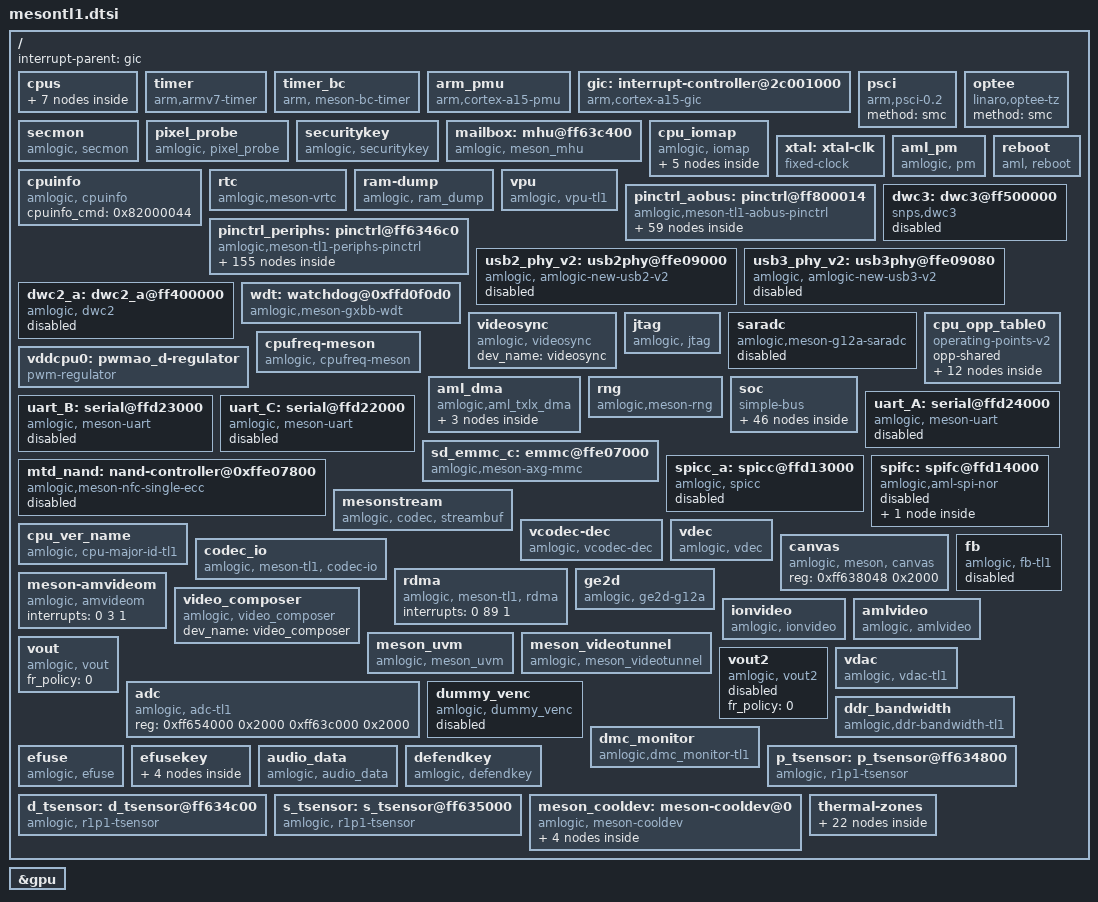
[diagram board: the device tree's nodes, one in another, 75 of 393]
// SPDX-License-Identifier: (GPL-2.0+ OR MIT)
/*
 * Copyright (c) 2021 Amlogic, Inc. All rights reserved.
 */

#include <dt-bindings/interrupt-controller/arm-gic.h>
#include <dt-bindings/gpio/meson-tl1-gpio.h>
#include <dt-bindings/gpio/gpio.h>
#include <dt-bindings/input/meson_rc.h>
#include <dt-bindings/input/input.h>
#include <dt-bindings/pwm/pwm.h>
#include <dt-bindings/pwm/meson.h>
#include <dt-bindings/clock/tl1-clkc.h>
#include <dt-bindings/clock/tl1-aoclkc.h>
#include <dt-bindings/clock/amlogic,tl1-audio-clk.h>
#include "mesong12a-bifrost.dtsi"
#include <dt-bindings/iio/adc/amlogic-saradc.h>
#include <dt-bindings/thermal/thermal.h>
#include "meson-ir-map.dtsi"
/ {
	interrupt-parent = <&gic>;
	#address-cells = <1>;
	#size-cells = <1>;

	cpus:cpus {
		#address-cells = <1>;
		#size-cells = <0>;
		#cooling-cells = <2>;/* min followed by max */
		CPU0:cpu@0 {
			device_type = "cpu";
			compatible = "arm,cortex-a9";
			reg = <0x0>;
			//timer=<&timer_a>;
			enable-method = "psci";
			clocks = <&clkc CLKID_CPU_CLK>,
				<&clkc CLKID_CPU_CLK_DYN>,
				<&clkc CLKID_SYS_PLL>,
				<&clkc CLKID_DSU_CLK>,
				<&clkc CLKID_DSU_CLK_FINAL>;
			clock-names = "core_clk",
				"low_freq_clk_parent",
				"high_freq_clk_parent",
				"dsu_clk",
				"dsu_pre_parent";
			operating-points-v2 = <&cpu_opp_table0>;
			/*set dynamic gp1 clk to val * 1000 *1000*/
			//dynamic_gp1_clk = <1000>;
			cpu-supply = <&vddcpu0>;
			cpu-idle-states = <&CPU_SLEEP_0 &SYSTEM_SLEEP_0>;
			//cpu-idle-states = <&SYSTEM_SLEEP_0>;
			voltage-tolerance = <0>;
			clock-latency = <50000>;
			#cooling-cells = <2>;
		};

		CPU1:cpu@1 {
			device_type = "cpu";
			compatible = "arm,cortex-a9";
			reg = <0x1>;
			//timer=<&timer_b>;
			enable-method = "psci";
			//clocks = <&clkc CLKID_CPU_CLK>,
			//	<&clkc CLKID_CPU_FCLK_P>,
			//	<&clkc CLKID_SYS_PLL>,
			//	<&clkc CLKID_DSU_CLK>,
			//	<&clkc CLKID_DSU_PRE_CLK>;
			//clock-names = "core_clk",
			//	"low_freq_clk_parent",
			//	"high_freq_clk_parent",
			//	"dsu_clk",
			//	"dsu_pre_parent";
			operating-points-v2 = <&cpu_opp_table0>;
			/*set dynamic gp1 clk to val * 1000 *1000*/
			dynamic_gp1_clk = <1000>;
			cpu-supply = <&vddcpu0>;
			cpu-idle-states = <&CPU_SLEEP_0 &SYSTEM_SLEEP_0>;
			//cpu-idle-states = <&SYSTEM_SLEEP_0>;
			voltage-tolerance = <0>;
			clock-latency = <50000>;
		};

		CPU2:cpu@2 {
			device_type = "cpu";
			compatible = "arm,cortex-a9";
			reg = <0x2>;
			//timer=<&timer_c>;
			enable-method = "psci";
			//clocks = <&clkc CLKID_CPU_CLK>,
			//	<&clkc CLKID_CPU_FCLK_P>,
			//	<&clkc CLKID_SYS_PLL>,
			//	<&clkc CLKID_DSU_CLK>,
			//	<&clkc CLKID_DSU_PRE_CLK>;
			//clock-names = "core_clk",
			//	"low_freq_clk_parent",
			//	"high_freq_clk_parent",
			//	"dsu_clk",
			//	"dsu_pre_parent";
			operating-points-v2 = <&cpu_opp_table0>;
			/*set dynamic gp1 clk to val * 1000 *1000*/
			dynamic_gp1_clk = <1000>;
			cpu-supply = <&vddcpu0>;
			cpu-idle-states = <&CPU_SLEEP_0 &SYSTEM_SLEEP_0>;
			//cpu-idle-states = <&SYSTEM_SLEEP_0>;
			voltage-tolerance = <0>;
			clock-latency = <50000>;
		};

		CPU3:cpu@3 {
			device_type = "cpu";
			compatible = "arm,cortex-a9";
			reg = <0x3>;
			//timer=<&timer_d>;
			enable-method = "psci";
			//clocks = <&clkc CLKID_CPU_CLK>,
			//	<&clkc CLKID_CPU_FCLK_P>,
			//	<&clkc CLKID_SYS_PLL>,
			//	<&clkc CLKID_DSU_CLK>,
			//	<&clkc CLKID_DSU_PRE_CLK>;
			//clock-names = "core_clk",
			//	"low_freq_clk_parent",
			//	"high_freq_clk_parent",
			//	"dsu_clk",
			//	"dsu_pre_parent";
			operating-points-v2 = <&cpu_opp_table0>;
			/*set dynamic gp1 clk to val * 1000 *1000*/
			dynamic_gp1_clk = <1000>;
			cpu-supply = <&vddcpu0>;
			cpu-idle-states = <&CPU_SLEEP_0 &SYSTEM_SLEEP_0>;
			//cpu-idle-states = <&SYSTEM_SLEEP_0>;
			voltage-tolerance = <0>;
			clock-latency = <50000>;
		};

		idle-states {
			entry-method = "arm,psci";
			CPU_SLEEP_0: cpu-sleep-0 {
				compatible = "arm,idle-state";
				arm,psci-suspend-param = <0x0010000>;
				local-timer-stop;
				entry-latency-us = <4000>;
				exit-latency-us = <4000>;
				min-residency-us = <9000>;
			};
			SYSTEM_SLEEP_0: system-sleep-0 {
				compatible = "arm,idle-state";
				arm,psci-suspend-param = <0x0000000>;
				entry-latency-us = <0x3fffffff>;
				exit-latency-us = <0x40000000>;
				min-residency-us = <0xffffffff>;
			};
		};
	};

	timer {
		compatible = "arm,armv7-timer";
		interrupts = <GIC_PPI 13 0xff01>,
			     <GIC_PPI 14 0xff01>,
			     <GIC_PPI 11 0xff01>,
			     <GIC_PPI 10 0xff01>;
	};

	timer_bc {
		compatible = "arm, meson-bc-timer";
		reg = <0xffd0f190  0x4  0xffd0f194  0x4>;
		timer_name = "Meson TimerF";
		clockevent-rating =<300>;
		clockevent-shift =<20>;
		clockevent-features =<0x23>;
		interrupts = <0 60 1>;
		bit_enable =<16>;
		bit_mode =<12>;
		bit_resolution =<0>;
	};

	arm_pmu {
		compatible = "arm,cortex-a15-pmu";
		/* clusterb-enabled; */
		interrupts = <GIC_SPI 137 IRQ_TYPE_LEVEL_HIGH>;
		reg = <0xff634680 0x4>;
		cpumasks = <0xf>;
		/* default 10ms */
		relax-timer-ns = <10000000>;
		/* default 10000us */
		max-wait-cnt = <10000>;
	};

	gic: interrupt-controller@2c001000 {
		compatible = "arm,cortex-a15-gic", "arm,cortex-a9-gic";
		#interrupt-cells = <3>;
		#address-cells = <0>;
		interrupt-controller;
		reg = <0xffc01000 0x1000>,
		      <0xffc02000 0x0100>;
		interrupts = <GIC_PPI 9 0xf04>;
	};

	psci {
		compatible = "arm,psci-0.2";
		method = "smc";
	};

	secmon {
		compatible = "amlogic, secmon";
		memory-region = <&secmon_reserved>;
		in_base_func = <0x82000020>;
		out_base_func = <0x82000021>;
		inout_size_func = <0x8200002a>;
		reserve_mem_size = <0x00300000>;
	};

	optee {
		compatible = "linaro,optee-tz";
		method = "smc";
	};

	pixel_probe: pixel_probe {
		compatible = "amlogic, pixel_probe";
		vpp_probe_func = <0x820000f1>;
		vdin_probe_func = <0x820000f2>;
	};

	securitykey {
		compatible = "amlogic, securitykey";
		status = "okay";
		storage_query = <0x82000060>;
		storage_read = <0x82000061>;
		storage_write = <0x82000062>;
		storage_tell = <0x82000063>;
		storage_verify = <0x82000064>;
		storage_status = <0x82000065>;
		storage_list = <0x82000067>;
		storage_remove = <0x82000068>;
		storage_in_func = <0x82000023>;
		storage_out_func = <0x82000024>;
		storage_block_func = <0x82000025>;
		storage_size_func = <0x82000027>;
		storage_set_enctype = <0x8200006A>;
		storage_get_enctype = <0x8200006B>;
		storage_version = <0x8200006C>;
	};

	mailbox: mhu@ff63c400 {
		status = "okay";
		compatible = "amlogic, meson_mhu";
		reg = <0xff63c400 0x4c>,   /* MHU registers */
		      <0xfffd7000 0x800>;   /* Payload area */
		interrupts = <GIC_SPI 209 IRQ_TYPE_EDGE_RISING>,
			     <GIC_SPI 210 IRQ_TYPE_EDGE_RISING>;
		#mbox-cells = <1>;
		mbox-names = "cpu_to_scp_low", "cpu_to_scp_high";
		mboxes = <&mailbox 0 &mailbox 1>;
	};

	cpu_iomap {
		compatible = "amlogic, iomap";
		#address-cells = <1>;
		#size-cells = <1>;
		ranges;

		io_cbus_base {
			reg = <0xffd00000 0x101000>;
		};
		io_apb_base {
			reg = <0xffe01000 0x19f000>;
		};
		io_aobus_base {
			reg = <0xff800000 0x100000>;
		};
		io_vapb_base {
			reg = <0xff900000 0x200000>;
		};
		io_hiu_base {
			reg = <0xff63c000 0x2000>;
		};
	};

	xtal: xtal-clk {
		compatible = "fixed-clock";
		clock-frequency = <24000000>;
		clock-output-names = "xtal";
		#clock-cells = <0>;
	};

	aml_pm {
		compatible = "amlogic, pm";
		status = "okay";
		device_name = "aml_pm";
		reg = <0xff8000a8 0x4>,
			<0xff80023c 0x4>,
			<0xff638634 0x4>, /* dmc_asr */
			<0xff63c19c 0x4>; /* cpu gp1 */
		reg-names = "dmc_asr",
			"cpu";
		dmc_asr_value = <0x3fe00>;
		//clocks = <&clkc CLKID_SWITCH_CLK81>,
		//	<&clkc CLKID_CLK81>,
		//	<&clkc CLKID_FIXED_PLL>,
		//	<&xtal>;
		//clock-names = "switch_clk81",
		//	"clk81",
		//	"fixed_pll",
		//	"xtal";
	};

	cpuinfo {
		compatible = "amlogic, cpuinfo";
		status = "okay";
		cpuinfo_cmd = <0x82000044>;
	};

	rtc{
		compatible = "amlogic,meson-vrtc";
		reg = <0xff8000a8 0x4>;	/*AO_DEBUG_REG2*/
		status = "okay";
		mboxes = <&mailbox 1>;
		mbox_data_packet;
	};

	reboot {
		compatible = "aml, reboot";
		sys_reset = <0x84000009>;
		sys_poweroff = <0x84000008>;
		reg = <0xff80023c 0x4>; /* SEC_AO_SEC_SD_CFG15 */
		status = "okay";
	};

	ram-dump {
		compatible = "amlogic, ram_dump";
		status = "okay";
		reg = <0xFF6345E0 4>;
		reg-names = "PREG_STICKY_REG8";
		store_device = "data";
	};

	securitykey {
		compatible = "amlogic, securitykey";
		status = "okay";
		storage_query = <0x82000060>;
		storage_read = <0x82000061>;
		storage_write = <0x82000062>;
		storage_tell = <0x82000063>;
		storage_verify = <0x82000064>;
		storage_status = <0x82000065>;
		storage_list = <0x82000067>;
		storage_remove = <0x82000068>;
		storage_in_func = <0x82000023>;
		storage_out_func = <0x82000024>;
		storage_block_func = <0x82000025>;
		storage_size_func = <0x82000027>;
		storage_set_enctype = <0x8200006A>;
		storage_get_enctype = <0x8200006B>;
		storage_version = <0x8200006C>;
	};

	vpu {
		compatible = "amlogic, vpu-tl1";
		status = "okay";
		reg =	<0xff63c000 0x200  /* hiu */
			 0xff900000 0x50000 /* vcbus */
			 0xffd00000 0x10a0  /* cbus */
			 0xff800000 0x100>; /* aobus */
		clocks = <&clkc CLKID_VAPB_SEL>,
			<&clkc CLKID_CLK81_VPU_INTR>,
			<&clkc CLKID_VPU_0>,
			<&clkc CLKID_VPU_1>,
			<&clkc CLKID_VPU>;
		clock-names = "vapb_clk",
			"vpu_intr_gate",
			"vpu_clk0",
			"vpu_clk1",
			"vpu_clk";
		clk_level = <7>;
		/* 0: 100.0M    1: 166.7M    2: 200.0M    3: 250.0M */
		/* 4: 333.3M    5: 400.0M    6: 500.0M    7: 666.7M */
	};

	pinctrl_aobus: pinctrl@ff800014 {
		compatible = "amlogic,meson-tl1-aobus-pinctrl";
		#address-cells = <1>;
		#size-cells = <1>;
		ranges;

		gpio_ao: ao-bank@ff800014 {
			reg = <0xff800014 0x8>,
				  <0xff800024 0x14>,
				  <0xff80001c 0x8>;
			reg-names = "mux", "gpio", "ds";
			gpio-controller;
			#gpio-cells = <2>;
			gpio-ranges = <&pinctrl_aobus 0 0 16>;
		};

		aoceca_mux:aoceca_mux {
			mux {
				groups = "cec_ao_a";
				function = "cec_ao";
			};
		};

		aocecb_mux:aocecb_mux {
			mux {
				groups = "cec_ao_b";
				function = "cec_ao";
			};
		};
	};

	pinctrl_periphs: pinctrl@ff6346c0 {
		compatible = "amlogic,meson-tl1-periphs-pinctrl";
		#address-cells = <1>;
		#size-cells = <1>;
		ranges;

		gpio: banks@ff6346c0 {
			reg = <0xff6346c0 0x40>,
				  <0xff6344e8 0x18>,
				  <0xff634520 0x18>,
				  <0xff634440 0x4c>,
				  <0xff634740 0x1c>;
			reg-names = "mux",
				"pull",
				"pull-enable",
				"gpio",
				"ds";
			gpio-controller;
			#gpio-cells = <2>;
			gpio-ranges = <&pinctrl_periphs 0 0 87>;
		};

		hdmirx_a_mux:hdmirx_a_mux {
			mux {
				groups = "hdmirx_a_hpd", "hdmirx_a_det",
					"hdmirx_a_sda", "hdmirx_a_sck";
				function = "hdmirx_a";
			};
		};

		hdmirx_b_mux:hdmirx_b_mux {
			mux {
				groups = "hdmirx_b_hpd", "hdmirx_b_det",
					"hdmirx_b_sda", "hdmirx_b_sck";
				function = "hdmirx_b";
			};
		};

		hdmirx_c_mux:hdmirx_c_mux {
			mux {
				groups = "hdmirx_c_hpd", "hdmirx_c_det",
					"hdmirx_c_sda", "hdmirx_c_sck";
				function = "hdmirx_c";
			};
		};

	};

	dwc3: dwc3@ff500000 {
		compatible = "snps,dwc3";
		status = "disabled";
		reg = <0xff500000 0x100000>;
		interrupts = <0 30 4>;
		usb-phy = <&usb2_phy_v2>, <&usb3_phy_v2>;
		cpu-type = "gxl";
		clock-src = "usb3.0";
		clocks = <&clkc CLKID_CLK81_USB_GENERAL>;
		clock-names = "usb_general";
	};

	usb2_phy_v2: usb2phy@ffe09000 {
		compatible = "amlogic, amlogic-new-usb2-v2";
		status = "disabled";
		reg = <0xffe09000 0x80
				0xffd01008 0x100
				0xff636000 0x2000
				0xff63a000 0x2000
				0xff658000 0x2000>;
		pll-setting-1 = <0x09400414>;
		pll-setting-2 = <0x927E0000>;
		pll-setting-3 = <0xac5f69e5>;
		pll-setting-4 = <0xfe18>;
		pll-setting-5 = <0x8000fff>;
		pll-setting-6 = <0x78000>;
		pll-setting-7 = <0xe0004>;
		pll-setting-8 = <0xe000c>;
		version = <1>;
	};

	usb3_phy_v2: usb3phy@ffe09080 {
		compatible = "amlogic, amlogic-new-usb3-v2";
		status = "disabled";
		reg = <0xffe09080 0x20>;
		phy-reg = <0xff646000>;
		phy-reg-size = <0x2000>;
		usb2-phy-reg = <0xffe09000>;
		usb2-phy-reg-size = <0x80>;
		interrupts = <0 16 4>;
	};

	dwc2_a: dwc2_a@ff400000 {
		compatible = "amlogic, dwc2";
		status = "disabled";
		device_name = "dwc2_a";
		reg = <0xff400000 0x40000>;
		interrupts = <0 31 4>;
		pl-periph-id = <0>; /** lm name */
		clock-src = "usb1"; /** clock src */
		port-id = <0>;  /** ref to mach/usb.h */
		port-type = <2>;        /** 0: otg, 1: host, 2: slave */
		port-speed = <0>; /** 0: default, high, 1: full */
		port-config = <0>; /** 0: default */
		/*0:default,1:single,2:incr,3:incr4,4:incr8,5:incr16,6:disable*/
		port-dma = <0>;
		port-id-mode = <0>; /** 0: hardware, 1: sw_host, 2: sw_slave*/
		usb-fifo = <728>;
		cpu-type = "v2";
		phy-reg = <0xffe09000>;
		phy-reg-size = <0xa0>;
		/** phy-interface: 0x0: amlogic-v1 phy, 0x1: synopsys phy **/
		/**                0x2: amlogic-v2 phy                    **/
		phy-interface = <0x2>;
		clocks = <&clkc CLKID_CLK81_USB_GENERAL
					&clkc CLKID_CLK81_USB1_TO_DDR>;
		clock-names = "usb_general",
					"usb1";
	};

	wdt: watchdog@0xffd0f0d0 {
		compatible = "amlogic,meson-gxbb-wdt";
		status = "okay";
		/* 0:userspace, 1:kernel */
		amlogic,feed_watchdog_mode = <1>;
		reg = <0xffd0f0d0 0x10>;
		clocks = <&xtal>;
	};

	videosync {
		compatible = "amlogic, videosync";
		dev_name = "videosync";
		status = "okay";
	};

	jtag {
		compatible = "amlogic, jtag";
		status = "okay";
		select = "disable"; /* disable/apao */
		pinctrl-names="jtag_a_pins";
		pinctrl-0=<&jtag_apao_pins>;
	};

	saradc: saradc {
		compatible = "amlogic,meson-g12a-saradc";
		status = "disabled";
		#io-channel-cells = <1>;
		clocks = <&xtal>,
			 <&clkc_AO CLKID_AO_SAR_ADC>,
			 <&clkc_AO CLKID_AO_SAR_ADC_CLK>,
			 <&clkc_AO CLKID_AO_SAR_ADC_SEL>;
		clock-names = "clkin", "core", "adc_clk", "adc_sel";
		interrupts = <GIC_SPI 200 IRQ_TYPE_EDGE_RISING>;
		reg = <0xff809000 0x48>;
	};

	vddcpu0: pwmao_d-regulator {
		compatible = "pwm-regulator";
		pwms = <&pwm_AO_cd MESON_PWM_1 1500 0>;
		regulator-name = "vddcpu0";
		regulator-min-microvolt = <689000>;
		regulator-max-microvolt = <1049000>;
		regulator-always-on;
		max-duty-cycle = <1500>;
		/* Voltage Duty-Cycle */
		voltage-table = <1049000 0>,
				<1039000 3>,
				<1029000 6>,
				<1019000 9>,
				<1009000 12>,
				<999000 14>,
				<989000 17>,
				<979000 20>,
				<969000 23>,
				<959000 26>,
				<949000 29>,
				<939000 31>,
				<929000 34>,
				<919000 37>,
				<909000 40>,
				<899000 43>,
				<889000 45>,
				<879000 48>,
				<869000 51>,
				<859000 54>,
				<849000 56>,
				<839000 59>,
				<829000 62>,
				<819000 65>,
				<809000 68>,
				<799000 70>,
				<789000 73>,
				<779000 76>,
				<769000 79>,
				<759000 81>,
				<749000 84>,
				<739000 87>,
				<729000 89>,
				<719000 92>,
				<709000 95>,
				<699000 98>,
				<689000 100>;
				status = "okay";
	};

	cpu_opp_table0: cpu_opp_table0 {
		compatible = "operating-points-v2";
		opp-shared;

		opp00 {
			opp-hz = /bits/ 64 <100000000>;
			opp-microvolt = <769000>;
		};
		opp01 {
			opp-hz = /bits/ 64 <250000000>;
			opp-microvolt = <769000>;
		};
		opp02 {
			opp-hz = /bits/ 64 <500000000>;
			opp-microvolt = <769000>;
		};
		opp03 {
			opp-hz = /bits/ 64 <667000000>;
			opp-microvolt = <779000>;
		};
		opp04 {
			opp-hz = /bits/ 64 <1000000000>;
			opp-microvolt = <789000>;
		};
		opp05 {
			opp-hz = /bits/ 64 <1200000000>;
			opp-microvolt = <789000>;
		};
		opp06 {
			opp-hz = /bits/ 64 <1404000000>;
			opp-microvolt = <799000>;
		};
		opp07 {
			opp-hz = /bits/ 64 <1500000000>;
			opp-microvolt = <809000>;
		};
		opp08 {
			opp-hz = /bits/ 64 <1608000000>;
			opp-microvolt = <819000>;
		};
		opp09 {
			opp-hz = /bits/ 64 <1704000000>;
			opp-microvolt = <859000>;
		};
		opp10 {
			opp-hz = /bits/ 64 <1800000000>;
			opp-microvolt = <919000>;
		};
		opp11 {
			opp-hz = /bits/ 64 <1908000000>;
			opp-microvolt = <989000>;
		};
	};

	cpufreq-meson {
		compatible = "amlogic, cpufreq-meson";
		status = "okay";
	};

	aml_dma {
		compatible = "amlogic,aml_txlx_dma";
		reg = <0xff63e000 0x48>;
		interrupts = <0 180 1>;

		aml_aes {
			compatible = "amlogic,aes_g12a_dma";
			dev_name = "aml_aes_dma";
			status = "okay";
		};

		aml_sha {
			compatible = "amlogic,sha_dma";
			dev_name = "aml_sha_dma";
			status = "okay";
		};

		aml_tdes {
			compatible = "amlogic,tdes_dma";
			dev_name = "aml_tdes_dma";
			status = "okay";
		};

	};

	rng {
		compatible = "amlogic,meson-rng";
		status = "okay";
		#address-cells = <1>;
		#size-cells = <1>;
		reg = <0xff630218 0x4>;
		quality = /bits/ 16 <1000>;
	};

	soc {
		compatible = "simple-bus";
		#address-cells = <1>;
		#size-cells = <1>;
		ranges;

		hiubus: hiubus@ff63c000 {
			compatible = "simple-bus";
			reg = <0xff63c000 0x2000>;
			#address-cells = <1>;
			#size-cells = <1>;
			ranges = <0x0 0xff63c000 0x2000>;

			hhi: system-controller@0 {
				compatible = "amlogic,meson-gx-hhi-sysctrl",
						"simple-mfd", "syscon";
				reg = <0 0x400>;

				clkc: clock-controller {
					compatible = "amlogic,tl1-clkc";
					#clock-cells = <1>;
					clocks = <&xtal>;
					clock-names = "xtal";
				};
			};
		};/* end of hiubus*/

		audiobus: audiobus@0xff600000 {
			compatible = "amlogic, audio-controller", "simple-bus";
			#address-cells = <1>;
			#size-cells = <1>;
			reg = <0xff600000 0x10000>;
			ranges = <0x0 0xff600000 0x10000>;
			reg-names = "audio_bus";
			chip_id = <0x2E>;
			clkaudio:audio_clocks {
				compatible = "amlogic, tl1-audio-clocks";
				#clock-cells = <1>;
				reg = <0x0 0xb0>;
			};

			ddr_manager {
				compatible = "amlogic, tl1-audio-ddr-manager";
				interrupts = <
					GIC_SPI 148 IRQ_TYPE_EDGE_RISING
					GIC_SPI 149 IRQ_TYPE_EDGE_RISING
					GIC_SPI 150 IRQ_TYPE_EDGE_RISING
					GIC_SPI 48 IRQ_TYPE_EDGE_RISING
					GIC_SPI 152 IRQ_TYPE_EDGE_RISING
					GIC_SPI 153 IRQ_TYPE_EDGE_RISING
					GIC_SPI 154 IRQ_TYPE_EDGE_RISING
					GIC_SPI 49 IRQ_TYPE_EDGE_RISING
				>;
				interrupt-names =
					"toddr_a", "toddr_b", "toddr_c",
					"toddr_d",
					"frddr_a", "frddr_b", "frddr_c",
					"frddr_d";
			};
			pinctrl_audio: pinctrl {
				compatible = "amlogic, tl1-audio-pinctrl";
				status = "okay";
			};
		};/* end of audiobus*/

		demux: demux {
			compatible = "amlogic, dmx";
			status = "okay";

			interrupts = <GIC_SPI 23 IRQ_TYPE_EDGE_RISING
				GIC_SPI 5 IRQ_TYPE_EDGE_RISING
				GIC_SPI 53 IRQ_TYPE_EDGE_RISING
				GIC_SPI 19 IRQ_TYPE_EDGE_RISING
				GIC_SPI 25 IRQ_TYPE_EDGE_RISING
				GIC_SPI 17 IRQ_TYPE_EDGE_RISING>;
			interrupt-names = "demux0_irq",
				"demux1_irq",
				"demux2_irq",
				"dvr0_irq",
				"dvr1_irq",
				"dvr2_irq";
		};

		/* Sound iomap */
		aml_snd_iomap {
			compatible = "amlogic, snd-iomap";
			status = "okay";
			#address-cells=<1>;
			#size-cells=<1>;
			ranges;
			pdm_bus {
				reg = <0xFF601000 0x400>;
			};
			audiobus_base {
				reg = <0xFF600000 0x1000>;
			};
			audiolocker_base {
				reg = <0xFF601400 0x400>;
			};
			eqdrc_base {
				reg = <0xFF602000 0x2000>;
			};
			reset_base {
				reg = <0xFFD01000 0x1000>;
			};
			vad_base {
				reg = <0xFF601800 0x800>;
			};
		};

		cbus: cbus@ffd00000 {
			compatible = "simple-bus";
			reg = <0xffd00000 0x27000>;
			#address-cells = <1>;
			#size-cells = <1>;
			ranges = <0x0 0xffd00000 0x27000>;

			clk-measure@18000 {
				compatible = "amlogic,meson-tl1-clk-measure";
				reg = <0x18000 0x10>;
			};

			i2c0: i2c@1f000 {
				compatible = "amlogic,meson-i2c";
				status = "disabled";
				reg = <0x1f000 0x20>;
				interrupts = <GIC_SPI 21 IRQ_TYPE_EDGE_RISING>,
					<GIC_SPI 91 IRQ_TYPE_EDGE_RISING>;
				#address-cells = <1>;
				#size-cells = <0>;
				clocks = <&clkc CLKID_CLK81_I2C>;
				clock-frequency = <100000>;
			};

			i2c1: i2c@1e000 {
				compatible = "amlogic,meson-i2c";
				status = "disabled";
				reg = <0x1e000 0x20>;
				interrupts = <GIC_SPI 214 IRQ_TYPE_EDGE_RISING>,
					<GIC_SPI 92 IRQ_TYPE_EDGE_RISING>;
				#address-cells = <1>;
				#size-cells = <0>;
				clocks = <&clkc CLKID_CLK81_I2C>;
				clock-frequency = <100000>;
			};

			i2c2: i2c@1d000 {
				compatible = "amlogic,meson-i2c";
				status = "disabled";
				reg = <0x1d000 0x20>;
				interrupts = <GIC_SPI 215 IRQ_TYPE_EDGE_RISING>,
					<GIC_SPI 94 IRQ_TYPE_EDGE_RISING>;
				#address-cells = <1>;
				#size-cells = <0>;
				clocks = <&clkc CLKID_CLK81_I2C>;
				clock-frequency = <100000>;
			};

			i2c3: i2c@1c000 {
				compatible = "amlogic,meson-i2c";
				status = "disabled";
				reg = <0x1c000 0x20>;
				interrupts = <GIC_SPI 39 IRQ_TYPE_EDGE_RISING>,
					<GIC_SPI 95 IRQ_TYPE_EDGE_RISING>;
				#address-cells = <1>;
				#size-cells = <0>;
				//clocks = <&clkc CLKID_I2C>;
				clock-frequency = <100000>;
			};

			gpio_intc: interrupt-controller@f080 {
				compatible = "amlogic,meson-gpio-intc",
						"amlogic,meson-tl1-gpio-intc";
				reg = <0xf080 0x10>;
				interrupt-controller;
				#interrupt-cells = <2>;
				amlogic,channel-interrupts =
					<64 65 66 67 68 69 70 71>;
				status = "okay";
			};

			pwm_ab: pwm@1b000 {
				compatible = "amlogic,tl1-ee-pwm";
				reg = <0x1b000 0x20>;
				#pwm-cells = <3>;
				clocks = <&xtal>,
						<&xtal>,
						<&xtal>,
						<&xtal>;
				clock-names = "clkin0",
						"clkin1",
						"clkin2",
						"clkin3";
				/* default xtal 24m  clkin0-clkin2 and
				 * clkin1-clkin3 should be set the same
				 */
				status = "disabled";
			};

			pwm_cd: pwm@1a000 {
				compatible = "amlogic,tl1-ee-pwm";
				reg = <0x1a000 0x20>;
				#pwm-cells = <3>;
				clocks = <&xtal>,
						<&xtal>,
						<&xtal>,
						<&xtal>;
				clock-names = "clkin0",
						"clkin1",
						"clkin2",
						"clkin3";
				status = "disabled";
			};

			pwm_ef: pwm@19000 {
				compatible = "amlogic,tl1-ee-pwm";
				reg = <0x19000 0x20>;
				#pwm-cells = <3>;
				clocks = <&xtal>,
						<&xtal>,
						<&xtal>,
						<&xtal>;
				clock-names = "clkin0",
						"clkin1",
						"clkin2",
						"clkin3";
				status = "disabled";
			};

			spicc0: spi@13000 {
				compatible = "amlogic,meson-tl1-spicc",
					     "amlogic,meson-g12a-spicc";
				reg = <0x13000 0x44>;
				interrupts = <GIC_SPI 81 IRQ_TYPE_LEVEL_HIGH>;
				//clocks = <&clkc CLKID_SPICC0>,
				//	 <&clkc CLKID_SPICC0_COMP>;
				//clock-names = "core", "comp";
				#address-cells = <1>;
				#size-cells = <0>;
				status = "disabled";
			};

			spicc1: spi@15000 {
				compatible = "amlogic,meson-tl1-spicc",
					     "amlogic,meson-g12a-spicc";
				reg = <0x15000 0x44>;
				interrupts = <GIC_SPI 90 IRQ_TYPE_LEVEL_HIGH>;
				//clocks = <&clkc CLKID_SPICC1>,
				//	 <&clkc CLKID_SPICC1_COMP>;
				clock-names = "core", "comp";
				#address-cells = <1>;
				#size-cells = <0>;
				status = "disabled";
			};
		};

		eth_phy: mdio-multiplexer@0xff64c000 {
			compatible = "amlogic,g12a-mdio-mux";
			reg = <0xff64c000 0xa4>;

			clocks = <&clkc CLKID_CLK81_ETH_PHY>,
				 <&xtal>,
				 <&clkc CLKID_MPLL_50M>;
			clock-names = "pclk", "clkin0", "clkin1";
			mdio-parent-bus = <&mdio0>;
			#address-cells = <1>;
			#size-cells = <0>;
			enet_type = <0>;

			ext_mdio: mdio@0 {
				reg = <0>;
				#address-cells = <1>;
				#size-cells = <0>;
			};

			int_mdio: mdio@1 {
				reg = <1>;
				#address-cells = <1>;
				#size-cells = <0>;

				internal_ephy: ethernet_phy@8 {
					compatible = "ethernet-phy-id0180.3301",
						     "ethernet-phy-ieee802.3-c22";
					interrupts = <GIC_SPI 9 IRQ_TYPE_LEVEL_HIGH>;
					reg = <8>;
					max-speed = <100>;
				};
			};
		};

		ethmac: ethernet@ff3f0000 {
			compatible = "amlogic,meson-axg-dwmac",
				     "snps,dwmac-3.70a",
				     "snps,dwmac";
			reg = <0xff3f0000 0x10000>,
			      <0xff634540 0x8>;
			interrupts = <GIC_SPI 8 IRQ_TYPE_LEVEL_HIGH>;
			interrupt-names = "macirq";
			clocks = <&clkc CLKID_CLK81_ETH_CORE>,
				 <&clkc CLKID_FCLK_DIV2>,
				 <&clkc CLKID_MPLL_50M>;
			clock-names = "stmmaceth", "clkin0", "clkin1";
			rx-fifo-depth = <4096>;
			tx-fifo-depth = <2048>;
			/*1:inphy; 2:exphy;*/
			internal_phy = <1>;
			mc_val = <0x4be04>;
			status = "disabled";

			mdio0: mdio {
				#address-cells = <1>;
				#size-cells = <0>;
				compatible = "snps,dwmac-mdio";
			};
		};

		aobus: aobus@ff800000 {
			compatible = "simple-bus";
			reg = <0xff800000 0xb000>;
			#address-cells = <1>;
			#size-cells = <1>;
			ranges = <0x0 0xff800000 0xb000>;

			cpu_version {
				compatible = "amlogic,meson-gx-ao-secure", "syscon";
				reg = <0x140 0x140>;
			};

			rti: sys-ctrl@0 {
				compatible = "amlogic,meson-gx-ao-sysctrl",
						"simple-mfd", "syscon";
				reg = <0x0 0x100>;
				#address-cells = <1>;
				#size-cells = <1>;
				ranges = <0x0 0x0 0x100>;

				clkc_AO: clock-controller {
					compatible = "amlogic,meson-tl1-aoclkc";
					#clock-cells = <1>;
					clocks = <&xtal>, <&clkc CLKID_CLK81>;
					clock-names = "xtal", "mpeg-clk";
				};
			};

			pwm_AO_ab: pwm@7000 {
				compatible = "amlogic,tl1-ao-pwm";
				reg = <0x7000 0x20>;
				#pwm-cells = <3>;
				clocks = <&xtal>,
					 <&xtal>,
					 <&xtal>,
					 <&xtal>;
				clock-names = "clkin0",
					      "clkin1",
					      "clkin2",
					      "clkin3";
				status = "disabled";
			};

			pwm_AO_cd: pwm@2000 {
				compatible = "amlogic,tl1-ao-pwm";
				reg = <0x2000 0x20>;
				#pwm-cells = <3>;
				clocks = <&xtal>,
					 <&xtal>,
					 <&xtal>,
					 <&xtal>;
				clock-names = "clkin0",
					      "clkin1",
					      "clkin2",
					      "clkin3";
				status = "okay";
			};

			uart_AO: serial@3000 {
				compatible = "amlogic, meson-uart";
				reg = <0x3000 0x18>;
				interrupts = <0 193 1>;
				status = "okay";
				clocks = <&xtal>;
				clock-names = "clk_uart";
				xtal_tick_en = <2>;
				fifosize = < 64 >;
				/* 0 not support; 1 support */
				support-sysrq = <0>;
			};

			uart_AO_B: serial@4000 {
				compatible = "amlogic, meson-uart";
				reg = <0x4000 0x18>;
				interrupts = <0 197 1>;
				status = "disabled";
				clocks = <&xtal &clkc_AO CLKID_AO_UART2>;
				clock-names = "clk_uart", "clk_gate";
				fifosize = < 64 >;
				pinctrl-names = "default";
				pinctrl-0 = <&ao_b_uart_pins1>;
			};

			ir: ir@8040 {
				compatible = "amlogic, meson-ir";
				reg = <0x8040 0x44>,
					<0x8000 0x20>;
				status = "disable";
				protocol = <REMOTE_TYPE_NEC>;
				interrupts = <GIC_SPI 196 IRQ_TYPE_EDGE_RISING>;
				map = <&custom_maps>;
				max_frame_time = <200>;
			};

			irblaster: meson-irblaster@14c {
				compatible = "amlogic, meson_irblaster";
				reg = <0x14c 0x10>,
					<0x40 0x4>;
				#irblaster-cells = <2>;
				interrupts = <GIC_SPI 198 IRQ_TYPE_EDGE_RISING>;
				status = "disabled";
			};

			i2c_AO: i2c@5000 {
				compatible = "amlogic,meson-i2c";
				status = "disabled";
				reg = <0x05000 0x20>;
				interrupts = <GIC_SPI 195 IRQ_TYPE_EDGE_RISING>,
					<GIC_SPI 201 IRQ_TYPE_EDGE_RISING>;
				#address-cells = <1>;
				#size-cells = <0>;
				clocks = <&clkc_AO CLKID_AO_I2C_M0>;
				clock-frequency = <100000>;
			};

			i2c_AO_slave:i2c_slave@6000 {
				compatible = "amlogic, meson-i2c-slave";
				status = "disabled";
				reg = <0x6000 0x20>;
				interrupts = <GIC_SPI 194 IRQ_TYPE_EDGE_RISING>;
				pinctrl-names="default";
				pinctrl-0=<&i2c_ao_slave_pins>;
			};
		};/* end of aobus */

		ion_dev {
			compatible = "amlogic, ion_dev";
			status = "okay";
			memory-region = <&ion_cma_reserved
					 &ion_fb_reserved>;
		};/* end of ion_dev*/
	}; /* end of soc*/

	uart_A: serial@ffd24000 {
		compatible = "amlogic, meson-uart";
		reg = <0xffd24000 0x18>;
		interrupts = <0 26 1>;
		status = "disabled";
		clocks = <&xtal
			&clkc CLKID_CLK81_UART0>;
		clock-names = "clk_uart",
			"clk_gate";
		fifosize = < 128 >;
		pinctrl-names = "default";
		pinctrl-0 = <&a_uart_pins>;
	};

	uart_B: serial@ffd23000 {
		compatible = "amlogic, meson-uart";
		reg = <0xffd23000 0x18>;
		interrupts = <0 75 1>;
		status = "disabled";
		clocks = <&xtal
			&clkc CLKID_CLK81_UART1>;
		clock-names = "clk_uart",
			"clk_gate";
		fifosize = < 64 >;
		pinctrl-names = "default";
		pinctrl-0 = <&b_uart_pins>;
	};

	uart_C: serial@ffd22000 {
		compatible = "amlogic, meson-uart";
		reg = <0xffd22000 0x18>;
		interrupts = <0 93 1>;
		status = "disabled";
		clocks = <&xtal
			&clkc CLKID_CLK81_UART2>;
		clock-names = "clk_uart",
			"clk_gate";
		fifosize = < 64 >;
		pinctrl-names = "default";
		pinctrl-0 = <&c_uart_pins>;
	};

	sd_emmc_c: emmc@ffe07000 {
		status = "okay";
		compatible = "amlogic,meson-axg-mmc";
		reg = <0xffe07000 0x800>,
			<0xffe07000 0x4>,//<0xFF63C25C 0x4>,
			<0xffe07000 0x4>;
		interrupts = <GIC_SPI 191 IRQ_TYPE_EDGE_RISING>;
		clocks = <&clkc CLKID_CLK81_SD_EMMC_C>,
			<&clkc CLKID_SD_EMMC_C_SEL>,
			<&clkc CLKID_SD_EMMC_C>,
			<&xtal>,
			<&clkc CLKID_GP0_PLL>,
			<&clkc CLKID_GP0_PLL>;
		clock-names = "core","mux0","mux1",
				"clkin0","clkin1","clkin2";
		card_type = <1>;
		tx_delay = <0x10>;
		src_clk_rate = <792000000>;
		mmc_debug_flag;
		disable-wp;
		no-sdio;
		no-sd;
	};

	spicc_a: spicc@ffd13000 {
		compatible = "amlogic, spicc";
		status = "disabled";
		device_id = <0>;
		reg = <0xffd13000 0x3c>;
		//clocks = <&clkc CLKID_SPICC0>,
		//	<&clkc CLKID_SPICC0_COMP>;
		//clock-names = "cts_spicc_hclk", "spicc_clk";
		clk_rate = <400000000>;
		//interrupts = <0 81 1>;
		enhance = <1>;
		dma_tx_threshold = <3>;
		dma_rx_threshold = <3>;
		dma_num_per_read_burst = <3>;
		dma_num_per_write_burst = <3>;
		ssctl = <0>;
		dma_en = <0>;
		delay_control = <0x15>;
		cs_delay = <10>;
		enhance_dlyctl = <0>;
		#address-cells = <1>;
		#size-cells = <0>;
	};

	spifc: spifc@ffd14000 {
		compatible = "amlogic,aml-spi-nor";
		status = "disabled";

		reg = <0xffd14000 0x80>;
		pinctrl-names = "default";
		pinctrl-0 = <&spifc_all_pins>;
		clock-names = "core";
		clocks = <&clkc CLKID_CLK81>;

		spi-nor@0 {
			compatible = "jedec,spi-nor";
			spifc-frequency = <40000000>;
			read-capability = <4>;/* dual read 1_1_2 */
			spifc-io-width = <4>;
		};
	};

	mtd_nand: nand-controller@0xffe07800 {
		compatible = "amlogic,meson-nfc-single-ecc";
		status = "disabled";
		reg = <0xffe07800 0x200>;
		interrupts = <GIC_SPI 34 IRQ_TYPE_EDGE_RISING>;

		pinctrl-names = "nand_norb_mod", "nand_cs_only";
		pinctrl-0 = <&all_nand_pins>;
		pinctrl-1 = <&nand_cs_pins>;
		clocks = <&clkc CLKID_CLK81_SD_EMMC_C>,
				<&clkc CLKID_FCLK_DIV2>;
		clock-names = "gate", "fdiv2pll";

		nand_clk_ctrl = <0xffe07000>;
	};

	mesonstream {
		compatible = "amlogic, codec, streambuf";
		status = "okay";
		clocks = <&clkc CLKID_CLK81_U_PARSER
			&clkc CLKID_CLK81_DEMUX
			&clkc CLKID_CLK81_AHB_ARB0
			&clkc CLKID_CLK81
			&clkc CLKID_CLK81_DOS
			&clkc CLKID_VDEC
			&clkc CLKID_HCODEC
			&clkc CLKID_HEVC
			&clkc CLKID_HEVCF>;
		clock-names = "parser_top",
			"demux",
			"ahbarb0",
			"clk_81",
			"vdec",
			"clk_vdec_mux",
			"clk_hcodec_mux",
			"clk_hevc_mux",
			"clk_hevcb_mux";
	};

	vcodec-dec {
		compatible = "amlogic, vcodec-dec";
		status = "okay";
	};

	vdec {
		compatible = "amlogic, vdec";
		status = "okay";
		interrupts = <0 3 1
			0 23 1
			0 32 1
			0 43 1
			0 44 1
			0 45 1>;
		interrupt-names = "vsync",
			"demux",
			"parser",
			"mailbox_0",
			"mailbox_1",
			"mailbox_2";
	};

	cpu_ver_name {
		compatible = "amlogic, cpu-major-id-tl1";
	};

	canvas: canvas {
		compatible = "amlogic, meson, canvas";
		status = "okay";
		reg = <0xff638048 0x2000>;
	};

	codec_io: codec_io {
		compatible = "amlogic, meson-tl1, codec-io";
		status = "okay";
		#address-cells=<1>;
		#size-cells=<1>;
		ranges;
		reg =	<0xffd00000 0x100000>,
			<0xff620000 0x10000>,
			<0xff63c000 0x2000>,
			<0xff800000 0x10000>,
			<0xff900000 0x40000>,
			<0xff638000 0x2000>,
			<0xff630000 0x2000>;
		reg-names = "cbus",
			    "dosbus",
			    "hiubus",
			    "aobus",
			    "vcbus",
			    "dmcbus",
			    "efusebus";
	};

	rdma {
		compatible = "amlogic, meson-tl1, rdma";
		status = "okay";
		interrupts = <0 89 1>;
		interrupt-names = "rdma";
	};

	fb: fb {
		compatible = "amlogic, fb-tl1";
		memory-region = <&logo_reserved>;
		status = "disabled";
		interrupts = <0 3 1
			0 56 1
			0 89 1>;
		interrupt-names = "viu-vsync", "viu2-vsync", "rdma";
		/* uboot logo,fb0/fb1 memory size,if afbcd fb0=0x01851000*/
		display_mode_default = "1080p60hz";
		scale_mode = <1>;
		/** 0:VPU free scale 1:OSD free scale 2:OSD super scale */
		display_size_default = <1920 1080 1920 2160 32>;
		/*1920*1080*4*3 = 0x17BB000*/
		clocks = <&clkc CLKID_VPU_CLKC_MUX>;
		clock-names = "vpu_clkc";
	};

	ge2d {
		compatible = "amlogic, ge2d-g12a";
		status = "okay";
		interrupts = <0 146 1>;
		interrupt-names = "ge2d";
		clocks = <&clkc CLKID_VAPB_SEL>,
			<&clkc CLKID_CLK81_G2D	>,
			<&clkc CLKID_VAPB>;
		clock-names = "clk_vapb_0",
			"clk_ge2d",
			"clk_ge2d_gate";
		reg = <0xff940000 0x10000>;
	};

	meson-amvideom {
		compatible = "amlogic, amvideom";
		status = "okay";
		interrupts = <0 3 1>;
		interrupt-names = "vsync";
	};

	video_composer {
		compatible = "amlogic, video_composer";
		dev_name = "video_composer";
		status = "okay";
	};

	ionvideo {
		compatible = "amlogic, ionvideo";
		status = "okay";
	};

	amlvideo {
		compatible = "amlogic, amlvideo";
		status = "okay";
	};

	meson_uvm {
		compatible = "amlogic, meson_uvm";
		status = "okay";
	};

	meson_videotunnel{
		compatible = "amlogic, meson_videotunnel";
		status = "okay";
	};

	vout: vout {
		compatible = "amlogic, vout";
		status = "okay";

		fr_policy = <0>;
	};

	vout2: vout2 {
		compatible = "amlogic, vout2";
		status = "disabled";
		//clocks = <&clkc CLKID_VPU_CLKC_P0_COMP>,
		//	<&clkc CLKID_VPU_CLKC_MUX>;
		clock-names = "vpu_clkc0",
			"vpu_clkc";

		fr_policy = <0>;
	};

	vdac {
		compatible = "amlogic, vdac-tl1";
		status = "okay";
	};

	adc: adc {
		compatible = "amlogic, adc-tl1";
		status = "okay";
		reg = <0xff654000 0x2000/* ana reg base */
			0xff63c000 0x2000>;/* afe reg base */
	};

	dummy_venc: dummy_venc {
		compatible = "amlogic, dummy_venc";
		status = "disabled";
		//clocks = <&clkc CLKID_VCLK2_ENCP
		//	&clkc CLKID_VCLK2_VENCP0
		//	&clkc CLKID_VCLK2_VENCP1
		//	&clkc CLKID_VCLK2_ENCI
		//	&clkc CLKID_VCLK2_VENCI0
		//	&clkc CLKID_VCLK2_VENCI1
		//	&clkc CLKID_VCLK2_ENCL
		//	&clkc CLKID_VCLK2_VENCL>;
		//clock-names = "encp_top_gate",
		//	"encp_int_gate0",
		//	"encp_int_gate1",
		//	"venci_top_gate",
		//	"enci_int_gate0",
		//	"enci_int_gate1",
		//	"encl_top_gate",
		//	"encl_int_gate";
	};

	ddr_bandwidth {
		compatible = "amlogic,ddr-bandwidth-tl1";
		status = "okay";
		reg = <0xff638000 0x100
		       0xff638c00 0x100>;
		interrupts = <0 52 1>;
		sec_base = <0xff639000>;
		interrupt-names = "ddr_bandwidth";
	};

	dmc_monitor {
		compatible = "amlogic,dmc_monitor-tl1";
		status = "okay";
		reg = <0xff638000 0x400>;
		reg_base = <0xff639000>;
		interrupts = <GIC_SPI 51 IRQ_TYPE_EDGE_RISING>;
	};

	efuse: efuse{
		compatible = "amlogic, efuse";
		reg = <0xff800228 0x4>;
		secureboot_mask = <0x00000010>;
		read_cmd = <0x82000030>;
		write_cmd = <0x82000031>;
		get_max_cmd = <0x82000033>;
		mem_in_base_cmd = <0x82000020>;
		mem_out_base_cmd = <0x82000021>;
		efuse_obj_cmd_status = <0x1>;
		key = <&efusekey>;
		clocks = <&clkc CLKID_CLK81_EFUSE>;
		clock-names = "efuse_clk";
		status = "okay";
	};

	efusekey:efusekey{
		keynum = <4>;
		key0 = <&key_0>;
		key1 = <&key_1>;
		key2 = <&key_2>;
		key3 = <&key_3>;
		key_0:key_0{
			keyname = "mac";
			offset = <0>;
			size = <6>;
		};
		key_1:key_1{
			keyname = "mac_bt";
			offset = <6>;
			size = <6>;
		};
		key_2:key_2{
			keyname = "mac_wifi";
			offset = <12>;
			size = <6>;
		};
		key_3:key_3{
			keyname = "usid";
			offset = <18>;
			size = <16>;
		};
	};

	audio_data: audio_data {
		compatible = "amlogic, audio_data";
		query_licence_cmd = <0x82000050>;
		mem_in_base_cmd = <0x82000020>;
		status = "okay";
	};

	defendkey: defendkey {
		compatible = "amlogic, defendkey";
		reg=<0xff800228 0x4>;
		mem_size = <0 0x100000>;
		status = "okay";
	};

	p_tsensor: p_tsensor@ff634800 {
		compatible = "amlogic, r1p1-tsensor";
		status = "okay";
		reg = <0xff634800 0x50>,
			<0xff800268 0x4>;
		cal_type = <0x1>;
		cal_coeff = <324 424 3159 9411>;
		rtemp = <115000>;
		interrupts = <GIC_SPI 35 IRQ_TYPE_LEVEL_HIGH>;
		clocks = <&clkc CLKID_TS>; /* CLKID_TS_COMP>;*/
		clock-names = "ts_comp";
		#thermal-sensor-cells = <1>;
	};

	d_tsensor: d_tsensor@ff634c00 {
		compatible = "amlogic, r1p1-tsensor";
		status = "okay";
		reg = <0xff634c00 0x50>,
			<0xff800230 0x4>;
		cal_type = <0x1>;
		cal_coeff = <324 424 3159 9411>;
		rtemp = <115000>;
		interrupts = <GIC_SPI 36 IRQ_TYPE_LEVEL_HIGH>;
		clocks = <&clkc CLKID_TS>; /* CLKID_TS_COMP>;*/
		clock-names = "ts_comp";
		#thermal-sensor-cells = <1>;
	};

	s_tsensor: s_tsensor@ff635000 {
		compatible = "amlogic, r1p1-tsensor";
		status = "okay";
		reg = <0xff635000 0x50>,
			<0xff80026c 0x4>;
		cal_type = <0x1>;
		cal_coeff = <324 424 3159 9411>;
		rtemp = <115000>;
		interrupts = <GIC_SPI 38 IRQ_TYPE_LEVEL_HIGH>;
		clocks = <&clkc CLKID_TS>; /* CLKID_TS_COMP>;*/
		clock-names = "ts_comp";
		#thermal-sensor-cells = <1>;
	};

	meson_cooldev: meson-cooldev@0 {
		status = "okay";
		compatible = "amlogic, meson-cooldev";
		cooling_devices {
			cpucore_cool_cluster0 {
				cluster_id = <0>;
				node_name = "cpucore_cool0";
				device_type = "cpucore";
			};
			gpufreq_cool {
				dyn_coeff = <140>;
				node_name = "bifrost";
				device_type = "gpufreq";
			};
		};
		cpucore_cool0:cpucore_cool0 {
			#cooling-cells = <2>; /* min followed by max */
		};
	};/*meson cooling devices end*/

	thermal-zones {
		soc_thermal: soc_thermal {
			polling-delay = <1000>;
			polling-delay-passive = <100>;
			sustainable-power = <1322>;
			thermal-sensors = <&p_tsensor 0>;
			trips {
				pswitch_on: trip-point@0 {
					temperature = <60000>;
					hysteresis = <5000>;
					type = "passive";
				};
				pcontrol: trip-point@1 {
					temperature = <75000>;
					hysteresis = <5000>;
					type = "passive";
				};
				phot: trip-point@2 {
					temperature = <85000>;
					hysteresis = <5000>;
					type = "hot";
				};
				pcritical: trip-point@3 {
					temperature = <110000>;
					hysteresis = <1000>;
					type = "critical";
				};
			};
			cooling-maps {
				cpufreq_cooling_map {
					trip = <&pcontrol>;
					cooling-device = <&CPU0 0 7>;
					contribution = <1024>;
				};
				cpucore_cooling_map {
					trip = <&phot>;
					cooling-device = <&cpucore_cool0 0 3>;
					contribution = <1024>;
				};
				gpufreq_cooling_map {
					trip = <&pcontrol>;
					cooling-device = <&gpu 0 4>;
					contribution = <1024>;
				};
			};
		};
		ddr_thermal: ddr_thermal {
			polling-delay = <2000>;
			polling-delay-passive = <1000>;
			sustainable-power = <1322>;
			thermal-sensors = <&d_tsensor 1>;
			trips {
				dswitch_on: trip-point@0 {
					temperature = <60000>;
					hysteresis = <5000>;
					type = "passive";
				};
				dcontrol: trip-point@1 {
					temperature = <75000>;
					hysteresis = <5000>;
					type = "passive";
				};
				dhot: trip-point@2 {
					temperature = <85000>;
					hysteresis = <5000>;
					type = "hot";
				};
				dcritical: trip-point@3 {
					temperature = <110000>;
					hysteresis = <1000>;
					type = "critical";
				};
			};
		};
		sar_thermal: sar_thermal {
			polling-delay = <2000>;
			polling-delay-passive = <1000>;
			sustainable-power = <1322>;
			thermal-sensors = <&s_tsensor 2>;
			trips {
				sswitch_on: trip-point@0 {
					temperature = <60000>;
					hysteresis = <5000>;
					type = "passive";
				};
				scontrol: trip-point@1 {
					temperature = <75000>;
					hysteresis = <5000>;
					type = "passive";
				};
				shot: trip-point@2 {
					temperature = <85000>;
					hysteresis = <5000>;
					type = "hot";
				};
				scritical: trip-point@3 {
					temperature = <110000>;
					hysteresis = <1000>;
					type = "critical";
				};
			};
		};
	};/*thermal zone end*/
}; /* end of / */

&pinctrl_aobus {
	sd_to_ao_uart_clr_pins: sd_to_ao_uart_clr_pins {
		mux {
			groups = "GPIOAO_0",
				   "GPIOAO_1",
				   "GPIOAO_2",
				   "GPIOAO_3",
				   "GPIOAO_4",
				   "GPIOAO_5",
				   "GPIOAO_6",
				   "GPIOAO_7",
				   "GPIOAO_8",
				   "GPIOAO_9",
				   "GPIOAO_10",
				   "GPIOAO_11",
				   "GPIOE_0",
				   "GPIOE_1",
				   "GPIOE_2",
				   "GPIO_TEST_N";
			function = "gpio_aobus";
		};
	};

	sd_to_ao_uart_pins: sd_to_ao_uart_pins {
		mux {
			groups = "uart_ao_a_tx",
				   "uart_ao_a_rx",
				   "uart_ao_a_cts",
				   "uart_ao_a_rts";
			function = "uart_ao_a";
			bias-pull-up;
			input-enable;
		};
	};

	remote_pins:remote_pin {
		mux {
			groups = "remote_input_ao";
			function = "remote_input_ao";
		};
	};

	pwm_ao_a_pins: pwm_ao_a {
		mux {
			groups = "pwm_ao_a";
			function = "pwm_ao_a";
		};
	};

	pwm_ao_a_hiz_pins: pwm_ao_a_hiz {
		mux {
			groups = "pwm_ao_a_hiz";
			function = "pwm_ao_a";
		};
	};

	pwm_ao_b_pins: pwm_ao_b {
		mux {
			groups = "pwm_ao_b";
			function = "pwm_ao_b";
		};
	};

	pwm_ao_c_pins1: pwm_ao_c_pins1 {
		mux {
			groups = "pwm_ao_c_4";
			function = "pwm_ao_c";
		};
	};

	pwm_ao_c_pins2: pwm_ao_c_pins2 {
		mux {
			groups = "pwm_ao_c_6";
			function = "pwm_ao_c";
		};
	};

	pwm_ao_c_hiz_pins1: pwm_ao_c_hiz1 {
		mux {
			groups = "pwm_ao_c_hiz_4";
			function = "pwm_ao_c";
		};
	};

	pwm_ao_c_hiz_pins2: pwm_ao_c_hiz2 {
		mux {
			groups = "pwm_ao_c_hiz_7";
			function = "pwm_ao_c";
		};
	};

	pwm_ao_d_pins1: pwm_ao_d_pins1 {
		mux {
			groups = "pwm_ao_d_5";
			function = "pwm_ao_d";
		};
	};

	pwm_ao_d_pins2: pwm_ao_d_pins2 {
		mux {
			groups = "pwm_ao_d_10";
			function = "pwm_ao_d";
		};
	};

	pwm_ao_d_pins3: pwm_ao_d_pins3 {
		mux {
			groups = "pwm_ao_d_e";
			function = "pwm_ao_d";
		};
	};

	pwm_a_e2: pwm_a_e2 {
		mux {
			groups = "pwm_a_e2";
			function = "pwm_a_e2";
		};
	};

	i2c_ao_2_pins:i2c_ao_2 {
		mux {
			groups = "i2c_ao_sck_2",
			"i2c_ao_sda_3";
			function = "i2c_ao";
			bias-pull-up;
			drive-strength = <3>;
		};
	};

	i2c_ao_2_pins_slp_input:i2c_ao_2_slp_input {
		mux {
			groups = "GPIOAO_2", "GPIOAO_3";
			function = "gpio_aobus";
			input-enable;
			bias-disable;
		};
	};

	i2c_ao_2_pins_slp_low:i2c_ao_2_slp_low {
		mux {
			groups = "GPIOAO_2", "GPIOAO_3";
			function = "gpio_aobus";
			output-low;
		};
	};

	i2c_ao_e_pins:i2c_ao_e {
		mux {
			groups = "i2c_ao_sck_e",
			"i2c_ao_sda_e";
			function = "i2c_ao";
			bias-pull-up;
			drive-strength = <3>;
		};
	};

	i2c_ao_e_pins_slp_input:i2c_ao_e_slp_input {
		mux {
			groups = "GPIOE_0", "GPIOE_1";
			function = "gpio_aobus";
			input-enable;
			bias-disable;
		};
	};

	i2c_ao_e_pins_slp_low:i2c_ao_e_slp_low {
		mux {
			groups = "GPIOE_0", "GPIOE_1";
			function = "gpio_aobus";
			output-low;
		};
	};

	i2c_ao_slave_pins:i2c_ao_slave {
		mux {
			groups = "i2c_ao_slave_sck",
			"i2c_ao_slave_sda";
			function = "i2c_ao_slave";
		};
	};

	ao_uart_pins:ao_uart {
		mux {
			groups = "uart_ao_a_rx",
				"uart_ao_a_tx";
			function = "uart_ao_a";
		};
	};

	ao_b_uart_pins1:ao_b_uart1 {
		mux {
			groups = "uart_ao_b_tx_2",
				"uart_ao_b_rx_3";
			function = "uart_ao_b";
			bias-pull-up;
			drive-strength = <3>;
		};
	};

	ao_b_uart_pins2:ao_b_uart2 {
		mux {
			groups = "uart_ao_b_tx_8",
				"uart_ao_b_rx_9";
			function = "uart_ao_b";
			bias-pull-up;
			drive-strength = <3>;
		};
	};

	irblaster_pins:irblaster_pin {
		mux {
			groups = "remote_out_ao";
			function = "remote_out_ao";
		};
	};

	irblaster_pins1:irblaster_pin1 {
		mux {
			groups = "remote_out_ao9";
			function = "remote_out_ao";
		};
	};

	jtag_apao_pins:jtag_apao_pin {
		mux {
			groups = "jtag_a_tdi",
			"jtag_a_tdo",
			"jtag_a_clk",
			"jtag_a_tms";
			function = "jtag_a";
		};
	};
};

&pinctrl_periphs {
	/* sdemmc portC */
	emmc_clk_gate_pins: emmc_clk_gate {
		mux {
			groups = "BOOT_10";
			function = "gpio_periphs";
			bias-pull-down;
			drive-strength = <2>;
		};
	};

	emmc_conf_pull_up: emmc_conf_pull_up {
		mux {
			groups = "emmc_nand_d7",
				 "emmc_nand_d6",
				 "emmc_nand_d5",
				 "emmc_nand_d4",
				 "emmc_nand_d3",
				 "emmc_nand_d2",
				 "emmc_nand_d1",
				 "emmc_nand_d0",
				 "emmc_clk",
				 "emmc_cmd";
			function = "emmc";
			input-enable;
			bias-pull-up;
			drive-strength = <2>;
		};
	};

	emmc_conf_pull_done: emmc_conf_pull_done {
		mux {
			groups = "emmc_nand_ds";
			function = "emmc";
			input-enable;
			bias-pull-down;
			drive-strength = <2>;
		};
	};

	/* sdemmc portB */
	sd_clk_cmd_pins: sd_clk_cmd_pins {
		mux {
			groups = "sdcard_cmd",
				   "sdcard_clk";
			function = "sdcard";
			input-enable;
			bias-pull-up;
			drive-strength = <3>;
		};
	};

	sd_all_pins: sd_all_pins {
		mux {
			groups = "sdcard_d0",
				   "sdcard_d1",
				   "sdcard_d2",
				   "sdcard_d3",
				   "sdcard_cmd",
				   "sdcard_clk";
			function = "sdcard";
			input-enable;
			bias-pull-up;
			drive-strength = <3>;
		};
	};

	sd_1bit_pins: sd_1bit_pins {
		mux {
			groups = "sdcard_d0",
					"sdcard_cmd",
					"sdcard_clk";
			function = "sdcard";
			input-enable;
			bias-pull-up;
			drive-strength = <3>;
		};
	};

	ao_to_sd_uart_pins: ao_to_sd_uart_pins {
		mux {
			groups ="uart_ao_a_rx_w3",
					"uart_ao_a_tx_w2",
					"uart_ao_a_rx_w7",
					"uart_ao_a_tx_w6",
					"uart_ao_a_rx_w11",
					"uart_ao_a_tx_w10";
			function = "uart_ao_a_ee";
			bias-pull-up;
			input-enable;
		};
	};

	all_nand_pins: all_nand_pins {
		mux {
			groups = "emmc_nand_d0",
				"emmc_nand_d1",
				"emmc_nand_d2",
				"emmc_nand_d3",
				"emmc_nand_d4",
				"emmc_nand_d5",
				"emmc_nand_d6",
				"emmc_nand_d7",
				"nand_ce0",
				"nand_ale",
				"nand_cle",
				"nand_wen_clk",
				"nand_ren_wr";
			function = "nand";
			input-enable;
			drive-strength = <3>;
		};
	};

	nand_cs_pins:nand_cs {
		mux {
			groups = "nand_ce0";
			function = "nand";
			drive-strength = <3>;
		};
	};

	/* sdemmc port */
	sdio_clk_gate_pins: sdio_clk_gate_pins {
		mux {
			groups = "GPIOC_4";
			function = "gpio_periphs";
			bias-pull-up;
			drive-strength = <3>;
		};
	};

	sdio_all_pins: sdio_all_pins {
		mux {
			groups = "sdcard_d0",
				"sdcard_d1",
				"sdcard_d2",
				"sdcard_d3",
				"sdcard_clk",
				"sdcard_cmd";
			function = "sdcard";
			input-enable;
			bias-pull-up;
			drive-strength = <3>;
		};
	};

	spifc_cs_pin:spifc_cs_pin {
		mux {
			groups = "nor_cs";
			function = "nor";
			bias-pull-up;
		};
	};

	spifc_pulldown: spifc_pulldown {
		mux {
			groups = "nor_d",
				"nor_q",
				"nor_c";
			function = "nor";
			bias-pull-down;
		};
	};

	spifc_pullup: spifc_pullup {
		mux {
			groups = "nor_cs";
			function = "nor";
			bias-pull-up;
		};
	};

	spifc_all_pins: spifc_all_pins {
		mux {
			groups =  "nor_d",
				"nor_q",
				"nor_c",
				"nor_hold",
				"nor_wp";
			function = "nor";
			input-enable;
			bias-pull-down;
		};
	};

	pwm_a_pins: pwm_a {
		mux {
			groups = "pwm_a";
			function = "pwm_a";
		};
	};

	pwm_b_pins1: pwm_b_pins1 {
		mux {
			groups = "pwm_b_c";
			function = "pwm_b";
		};
	};

	pwm_b_pins2: pwm_b_pins2 {
		mux {
			groups = "pwm_b_z";
			function = "pwm_b";
		};
	};

	pwm_c_pins1: pwm_c_pins1 {
		mux {
			groups = "pwm_c_dv";
			function = "pwm_c";
		};
	};

	pwm_c_pins2: pwm_c_pins2 {
		mux {
			groups = "pwm_c_h";
			function = "pwm_c";
		};
	};

	pwm_c_pins3: pwm_c_pins3 {
		mux {
			groups = "pwm_c_z";
			function = "pwm_c";
		};
	};

	pwm_d_pins1: pwm_d_pins1 {
		mux {
			groups = "pwm_d_dv";
			function = "pwm_d";
		};
	};

	pwm_d_pins2: pwm_d_pins2 {
		mux {
			groups = "pwm_d_z";
			function = "pwm_d";
		};
	};

	pwm_e_pins1: pwm_e1 {
		mux {
			groups = "pwm_e_dv";
			function = "pwm_e";
		};
	};

	pwm_e_pins2: pwm_e2 {
		mux {
			groups = "pwm_e_z";
			function = "pwm_e";
		};
	};

	pwm_f_pins1: pwm_f_pins1 {
		mux {
			groups = "pwm_f_dv";
			function = "pwm_f";
		};
	};

	pwm_f_pins2: pwm_f_pins2 {
		mux {
			groups = "pwm_f_z";
			function = "pwm_f";
		};
	};

	i2c0_c_pins:i2c0_c {
		mux {
			groups = "i2c0_sda_c",
				"i2c0_sck_c";
			function = "i2c0";
			bias-pull-up;
			drive-strength = <3>;
		};
	};

	i2c0_c_pins_slp_input:i2c0_c_slp_input {
		mux {
			groups = "GPIOC_8", "GPIOC_9";
			function = "gpio_periphs";
			input-enable;
			bias-disable;
		};
	};

	i2c0_c_pins_slp_low:i2c0_c_slp_low {
		mux {
			groups = "GPIOC_8", "GPIOC_9";
			function = "gpio_periphs";
			output-low;
		};
	};

	i2c0_dv_pins:i2c0_dv {
		mux {
			groups = "i2c0_sda_dv",
				"i2c0_sck_dv";
			function = "i2c0";
			bias-pull-up;
			drive-strength = <3>;
		};
	};

	i2c0_dv_pins_slp_input:i2c0_dv_slp_input {
		mux {
			groups = "GPIODV_0", "GPIODV_1";
			function = "gpio_periphs";
			input-enable;
			bias-disable;
		};
	};

	i2c0_dv_pins_slp_low:i2c0_dv_slp_low {
		mux {
			groups = "GPIODV_0", "GPIODV_1";
			function = "gpio_periphs";
			output-low;
		};
	};

	i2c1_z_pins:i2c1_z {
		mux {
			groups = "i2c1_sda_z",
				"i2c1_sck_z";
			function = "i2c1";
			bias-pull-up;
			drive-strength = <3>;
		};
	};

	/*
	 * i2c sleep mode1: set the gpio the input
	 * in this scene, pull up power is off
	 */
	i2c1_z_pins_slp_input:i2c1_z_slp_input {
		mux {
			groups = "GPIOZ_1", "GPIOZ_2";
			function = "gpio_periphs";
			input-enable;
			bias-disable;
		};
	};

	/*
	 * i2c sleep mode2: set the gpio low
	 * in this scene, pull up power is on
	 */
	i2c1_z_pins_slp_low:i2c1_z_slp_low {
		mux {
			groups = "GPIOZ_1", "GPIOZ_2";
			function = "gpio_periphs";
			output-low;
		};
	};

	i2c1_h_pins:i2c1_h {
		mux {
			groups = "i2c1_sda_h",
				"i2c1_sck_h";
			function = "i2c1";
			bias-pull-up;
			drive-strength = <3>;
		};
	};

	i2c1_h_pins_slp_input:i2c1_h_slp_input {
		mux {
			groups = "GPIOH_21", "GPIOH_22";
			function = "gpio_periphs";
			input-enable;
			bias-disable;
		};
	};

	i2c1_h_pins_slp_low:i2c1_h_slp_low {
		mux {
			groups = "GPIOH_21", "GPIOH_22";
			function = "gpio_periphs";
			output-low;
		};
	};

	i2c2_h_pins:i2c2_h {
		mux {
			groups = "i2c2_sda_h",
				"i2c2_sck_h";
			function = "i2c2";
			bias-pull-up;
			drive-strength = <3>;
		};
	};

	i2c2_h_pins_slp_input:i2c2_h_slp_input {
		mux {
			groups = "GPIOH_19", "GPIOH_20";
			function = "gpio_periphs";
			input-enable;
			bias-disable;
		};
	};

	i2c2_h_pins_slp_low:i2c2_h_slp_low {
		mux {
			groups = "GPIOH_19", "GPIOH_20";
			function = "gpio_periphs";
			output-low;
		};
	};

	i2c2_z_pins:i2c2_z {
		mux {
			groups = "i2c2_sda_z",
				"i2c2_sck_z";
			function = "i2c2";
			bias-pull-up;
			drive-strength = <3>;
		};
	};

	i2c2_z_pins_slp_input:i2c2_z_slp_input {
		mux {
			groups = "GPIOZ_9", "GPIOZ_10";
			function = "gpio_periphs";
			input-enable;
			bias-disable;
		};
	};

	i2c2_z_pins_slp_low:i2c2_z_slp_low {
		mux {
			groups = "GPIOZ_9", "GPIOZ_10";
			function = "gpio_periphs";
			output-low;
		};
	};

	i2c3_h1_pins:i2c3_h1 {
		mux {
			groups = "i2c3_sda_h1",
				"i2c3_sck_h0";
			function = "i2c3";
			bias-pull-up;
			drive-strength = <3>;
		};
	};

	i2c3_h1_pins_slp_input:i2c3_h1_slp_input {
		mux {
			groups = "GPIOH_0", "GPIOH_1";
			function = "gpio_periphs";
			input-enable;
			bias-disable;
		};
	};

	i2c3_h1_pins_slp_low:i2c3_h1_slp_low {
		mux {
			groups = "GPIOH_0", "GPIOH_1";
			function = "gpio_periphs";
			output-low;
		};
	};

	i2c3_h20_pins:i2c3_h3 {
		mux {
			groups = "i2c3_sda_h20",
				"i2c3_sck_h19";
			function = "i2c3";
			bias-pull-up;
			drive-strength = <3>;
		};
	};

	i2c3_h20_pins_slp_input:i2c3_h20_slp_input {
		mux {
			groups = "GPIOH_19", "GPIOH_20";
			function = "gpio_periphs";
			input-enable;
			bias-disable;
		};
	};

	i2c3_h20_pins_slp_low:i2c3_h20_slp_low {
		mux {
			groups = "GPIOH_19", "GPIOH_20";
			function = "gpio_periphs";
			output-low;
		};
	};

	i2c3_dv_pins:i2c3_dv {
		mux {
			groups = "i2c3_sda_dv",
				"i2c3_sck_dv";
			function = "i2c3";
			bias-pull-up;
			drive-strength = <3>;
		};
	};

	i2c3_dv_pins_slp_input:i2c3_dv_slp_input {
		mux {
			groups = "GPIODV_9", "GPIODV_10";
			function = "gpio_periphs";
			input-enable;
			bias-disable;
		};
	};

	i2c3_dv_pins_slp_low:i2c3_dv_slp_low {
		mux {
			groups = "GPIODV_9", "GPIODV_10";
			function = "gpio_periphs";
			output-low;
		};
	};

	i2c3_c_pins:i2c3_c {
		mux {
			groups = "i2c3_sda_c",
				"i2c3_sck_c";
			function = "i2c3";
			bias-pull-up;
			drive-strength = <3>;
		};
	};

	i2c3_c_pins_slp_input:i2c3_c_slp_input {
		mux {
			groups = "GPIOC_13", "GPIOC_14";
			function = "gpio_periphs";
			input-enable;
			bias-disable;
		};
	};

	i2c3_c_pins_slp_low:i2c3_c_slp_low {
		mux {
			groups = "GPIOC_13", "GPIOC_14";
			function = "gpio_periphs";
			output-low;
		};
	};

	spicc0_pins_h: spicc0_pins_h {
		mux {
			groups = "spi0_mosi_h",
				 "spi0_miso_h",
				 "spi0_clk_h";
			function = "spi0";
			drive-strength = <3>;
		};
	};

	spicc1_pins_dv: spicc1_pins_dv {
		mux {
			groups = "spi1_mosi_dv",
				 "spi1_miso_dv",
				 "spi1_clk_dv";
			function = "spi1";
			drive-strength = <1>;
		};
	};

	internal_eth_pins: internal_eth_pins {
		mux {
			groups = "eth_link_led",
				"eth_act_led";
			function = "eth";
		};
	};

	internal_gpio_pins: internal_gpio_pins {
		mux {
			groups = "GPIOH_0",
				"GPIOH_1";
			function = "gpio_periphs";
			bias-disable;
			input-enable;
		};
	};

	external_eth_pins: external_eth_pins {
		mux {
			groups = "eth_mdio",
			"eth_mdc",
			"eth_rgmii_rx_clk",
			"eth_rx_dv",
			"eth_rxd0",
			"eth_rxd1",
			"eth_rxd2_rgmii",
			"eth_rxd3_rgmii",
			"eth_rgmii_tx_clk",
			"eth_txen",
			"eth_txd0",
			"eth_txd1",
			"eth_txd2_rgmii",
			"eth_txd3_rgmii";
			function = "eth";
			drive-strength = <3>;
		};
	};

	a_uart_pins:a_uart {
		mux {
			groups = "uart_a_tx",
				"uart_a_rx",
				"uart_a_cts",
				"uart_a_rts";
			function = "uart_a";
			bias-pull-up;
			drive-strength = <3>;
		};
	};

	b_uart_pins:b_uart {
		mux {
			groups = "uart_b_tx",
				"uart_b_rx";
			function = "uart_b";
			bias-pull-up;
			drive-strength = <3>;
		};
	};

	c_uart_pins:c_uart {
		mux {
			groups = "uart_c_tx",
				"uart_c_rx";
			function = "uart_c";
			bias-pull-up;
			drive-strength = <3>;
		};
	};

	atvdemod_agc_pins: atvdemod_agc_pins {
		mux {
			groups = "atv_if_agc_dv";
			function = "atv";
		};
	};

	dtvdemod_agc_pins: dtvdemod_agc_pins {
		mux {
			groups = "dtv_if_agc_dv2";
			function = "dtv";
		};
	};

	lcd_vbyone_pins: lcd_vbyone_pin {
		mux {
			groups = "vx1_lockn","vx1_htpdn";
			function = "vx1";
		};
	};
	lcd_vbyone_off_pins: lcd_vbyone_off_pin {
		mux {
			groups = "GPIOH_15","GPIOH_16";
			function = "gpio_periphs";
			input-enable;
		};
	};

	lcd_tcon_p2p_pins: lcd_tcon_p2p_pin {
		mux {
			groups = "tcon_0","tcon_1","tcon_2","tcon_3",
				"tcon_4","tcon_5","tcon_6","tcon_7",
				"tcon_8","tcon_9","tcon_10","tcon_11",
				"tcon_12","tcon_13","tcon_14","tcon_15",
				"tcon_lock";
			function = "tcon";
		};
	};
	lcd_tcon_p2p_usit_pins: lcd_tcon_p2p_usit_pin {
		mux {
			groups = "tcon_0","tcon_1","tcon_2","tcon_3",
				"tcon_4","tcon_5","tcon_6","tcon_7",
				"tcon_8","tcon_9","tcon_10","tcon_11",
				"tcon_12","tcon_13","tcon_14","tcon_15",
				"tcon_sfc_h16";
			function = "tcon";
		};
	};
	lcd_tcon_p2p_off_pins: lcd_tcon_p2p_off_pin {
		mux {
			groups = "GPIOH_0","GPIOH_1","GPIOH_2","GPIOH_3",
				"GPIOH_4","GPIOH_5","GPIOH_6","GPIOH_7",
				"GPIOH_8","GPIOH_9","GPIOH_10","GPIOH_11",
				"GPIOH_12","GPIOH_13","GPIOH_14","GPIOH_15",
				"GPIOH_16";
			function = "gpio_periphs";
			input-enable;
		};
	};
	lcd_tcon_mlvds_pins: lcd_tcon_mlvds_pin {
		mux {
			groups = "tcon_0","tcon_1","tcon_2","tcon_3",
				"tcon_4","tcon_5","tcon_6","tcon_7",
				"tcon_8","tcon_9","tcon_10","tcon_11",
				"tcon_12","tcon_13","tcon_14","tcon_15";
			function = "tcon";
		};
	};
	lcd_tcon_mlvds_off_pins: lcd_tcon_mlvds_off_pin {
		mux {
			groups = "GPIOH_0","GPIOH_1","GPIOH_2","GPIOH_3",
				"GPIOH_4","GPIOH_5","GPIOH_6","GPIOH_7",
				"GPIOH_8","GPIOH_9","GPIOH_10","GPIOH_11",
				"GPIOH_12","GPIOH_13","GPIOH_14","GPIOH_15";
			function = "gpio_periphs";
			input-enable;
		};
	};
};

&gpu{
	clocks = <&clkc CLKID_MALI>;
	clock-names = "gpu_mux";

	/*
	 * Mali clocking is provided by two identical clock paths
	 * MALI_0 and MALI_1 muxed to a single clock by a glitch
	 * free mux to safely change frequency while running.
	 */
	assigned-clocks = <&clkc CLKID_MALI_0_SEL>,
			  <&clkc CLKID_MALI_0>,
			  <&clkc CLKID_MALI>; /* Glitch free mux */
	assigned-clock-parents = <&clkc CLKID_FCLK_DIV4>,
				 <0>, /* Do Nothing */
				 <&clkc CLKID_MALI_0>;
	assigned-clock-rates = <0>, /* Do Nothing */
				<500000000>,
				<0>; /* Do Nothing */

	tbl =  <&dvfs285_cfg
		&dvfs400_cfg
		&dvfs500_cfg
		&dvfs666_cfg
		&dvfs800_cfg
		&dvfs800_cfg>;
};
